# MAX32600 register map
File version: 1.0
Registers are 32-bit, read-write, reset 0x0 unless marked. A register's access mark holds for its fields unless they carry their own. Offsets are from the block's base; [hi:lo] are bit positions; 'fields as' and 'values as' point back to an identical list.

## AES — AES Cryptographic Engine
Base 0x40011400
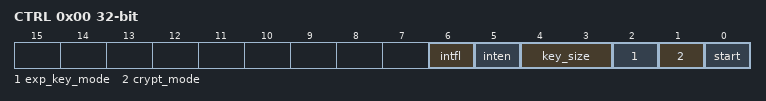
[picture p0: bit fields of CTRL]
0x00 CTRL — AES Control and Status
  [6] intfl write-1-clears — AES Interrupt Flag
  [5] inten — AES Interrupt Enable
  [4:3] key_size — AES Key Size Select
    0=#doxy_brief (Settings for AES_CTRL.key_size); 0=Use 128-bit AES key size; 1=Use 192-bit AES key size; 2=Use 256-bit AES key size
  [2] exp_key_mode — AES Expanded Key Mode
    0=#doxy_brief (Settings for AES_CTRL.exp_key_mode); 0=CALC_NEW_EXP_KEY (Calculate new expanded key for this operation.); 1=USE_LAST_EXP_KEY (Use expanded key calculated by the last operation.)
  [1] crypt_mode — AES Encrypt/Decrypt Mode
    0=#doxy_brief (Settings for AES_CTRL.crypt_mode); 0=ENCRYPT_MODE (Perform AES encryption operation.); 1=DECRYPT_MODE (Perform AES decryption operation.)
  [0] start — AES Start/Busy
0x08 ERASE_ALL — Write to Trigger AES Memory Erase

## MAA — MAA Cryptographic Engine
Base 0x40011800
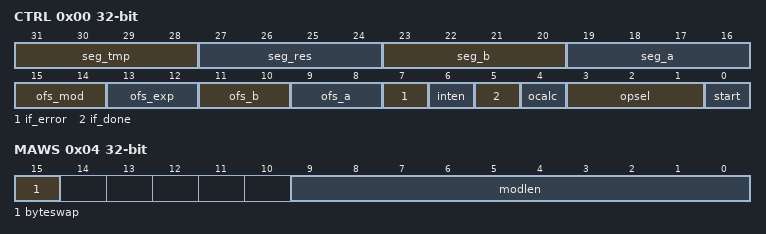
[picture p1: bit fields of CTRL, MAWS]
0x00 CTRL — MAA Control, Configuration and Status
  [31:28] seg_tmp — Temporary Memory Segment Select
  [27:24] seg_res — Result Memory Segment Select
  [23:20] seg_b — Operand B Memory Segment Select
  [19:16] seg_a — Operand A Memory Segment Select
  [15:14] ofs_mod — Modulus Memory Select
  [13:12] ofs_exp — Exponent Memory Offset Select
  [11:10] ofs_b — Operand B Memory Offset Select
  [9:8] ofs_a — Operand A Memory Offset Select
  [7] if_error — Interrupt Flag - Error
  [6] inten — MAA Interrupt Enable
  [5] if_done — Interrupt Flag - Calculation Done
  [4] ocalc — Optimized Calculation Control
  [3:1] opsel — Select Operation Type
    0=#doxy_brief (Operation select for MAA.); 0=EXP (Exponentiation.); 1=SQR (Square operation.); 2=MUL (Multiply.); 3=SQRMUL (Square operation followed by multiply.); 4=ADD (Addition.); 5=SUB (Subtraction.)
  [0] start — Start MAA Calculation
0x04 MAWS — MAA Word (Operand) Size, Big/Little Endian Mode Select
  [15] byteswap — Big Endian Byte Mode
  [9:0] modlen — MAA Word Size

## TMR0 — 16/32 bit Timer/Counters
Base 0x40012000
Same registers: TMR1 0x40013000, TMR2 0x40014000, TMR3 0x40015000
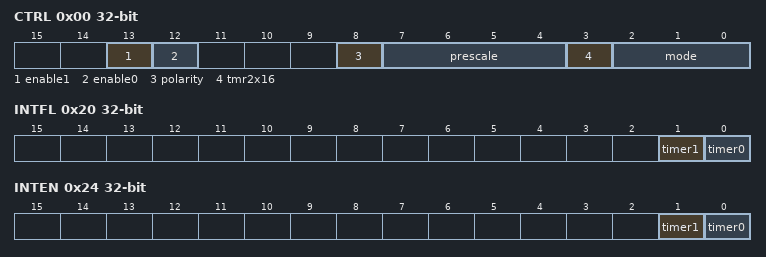
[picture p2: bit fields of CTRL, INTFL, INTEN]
0x00 CTRL — Timer Control Register
  [13] enable1 — Enable 16-bit timer 1
  [12] enable0 — Enable 32-bit timer / 16-bit timer 0
  [8] polarity — Timer I/O Polarity
  [7:4] prescale — Timer Clock Prescale Setting
  [3] tmr2x16 — Dual 16-bit Timer Mode
  [2:0] mode — Operating Modes for 32-bit/16-bit Timers
0x04 COUNT32 — [32 bit] Current Count Value
0x08 TERM_CNT32 — [32 bit] Terminal Count Setting
0x0C PWM_CAP32 — [32 bit] PWM Compare Setting or Capture/Measure Value
0x10 COUNT16_0 — [16 bit] Current Count Value, 16-bit Timer 0
  [15:0] value — Count Value
0x14 TERM_CNT16_0 — [16 bit] Terminal Count Setting, 16-bit Timer 0
  [15:0] term_count — Terminal Count Setting
0x18 COUNT16_1 — [16 bit] Current Count Value, 16-bit Timer 1
  [15:0] value — Count Value
0x1C TERM_CNT16_1 — [16 bit] Terminal Count Setting, 16-bit Timer 1
  [15:0] term_count — Terminal Count Setting
0x20 INTFL — Timer Module Interrupt Flags
  [1] timer1 write-1-clears — Interrupt Flag for 16-bit Timer 1
  [0] timer0 write-1-clears — Interrupt Flag for 32-bit Timer / 16-bit Timer 0
0x24 INTEN — Timer Module Interrupt Enable/Disable Settings
  [1] timer1 — Interrupt Enable for 16-bit Timer 1
  [0] timer0 — Interrupt Enable for 32-bit Timer / 16-bit Timer 0

## WDT0 — Watchdog Timers
Base 0x40021000
Same registers: WDT1 0x40022000
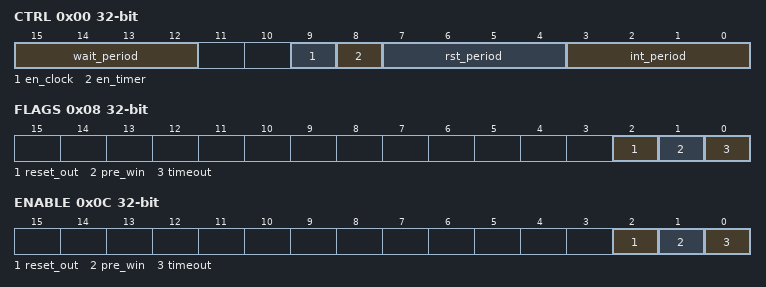
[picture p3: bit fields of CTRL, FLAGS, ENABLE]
0x00 CTRL — WDT0 - Watchdog Timer Control Register
  [15:12] wait_period — Period from WDT Clear to Clear Window Begin
    0=#doxy_brief (Defines watchdog timer periods.); 0=2_31_CLKS (2^31 WDT clocks.); 1=2_30_CLKS (2^30 WDT clocks.); 2=2_29_CLKS (2^29 WDT clocks.); 3=2_28_CLKS (2^28 WDT clocks.); 4=2_27_CLKS (2^27 WDT clocks.); 5=2_26_CLKS (2^26 WDT clocks.); 6=2_25_CLKS (2^25 WDT clocks.); 7=2_24_CLKS (2^24 WDT clocks.); 8=2_23_CLKS (2^23 WDT clocks.); 9=2_22_CLKS (2^22 WDT clocks.); 16=2_21_CLKS (2^21 WDT clocks.); 17=2_20_CLKS (2^20 WDT clocks.); 18=2_19_CLKS (2^19 WDT clocks.); 19=2_18_CLKS (2^18 WDT clocks.); 20=2_17_CLKS (2^17 WDT clocks.); 21=2_16_CLKS (2^16 WDT clocks.)
  [9] en_clock — Watchdog Clock Gate
  [8] en_timer — Watchdg Timer Enable
  [7:4] rst_period — Period from WDT Clear to Reset Flag Set
    values as wait_period
  [3:0] int_period — Period from WDT Clear to Interrupt Flag Set
    values as wait_period
0x04 CLEAR — WDT0 - Watchdog Clear Register (Feed Dog)
0x08 FLAGS — WDT0 - Watchdog Interrupt and Reset Flags
  [2] reset_out write-1-clears — Watchdog Reset Flag
  [1] pre_win write-1-clears — Watchdog Pre-Window Clear Interrupt Flag
  [0] timeout write-1-clears — Watchdog Timeout Interrupt Flag
0x0C ENABLE — WDT0 - Interrupt/Reset Enable/Disable Controls
  [2] reset_out — Enable Watchdog Reset Output
  [1] pre_win — Enable Watchdog Pre-Window Reset Interrupt
  [0] timeout — Enable Watchdog Interrupt
0x14 LOCK_CTRL — WDT0 - Register Setting Lock for WDT0_CTRL
  [7:0] wdlock — Lock for WDT CTRL Register
